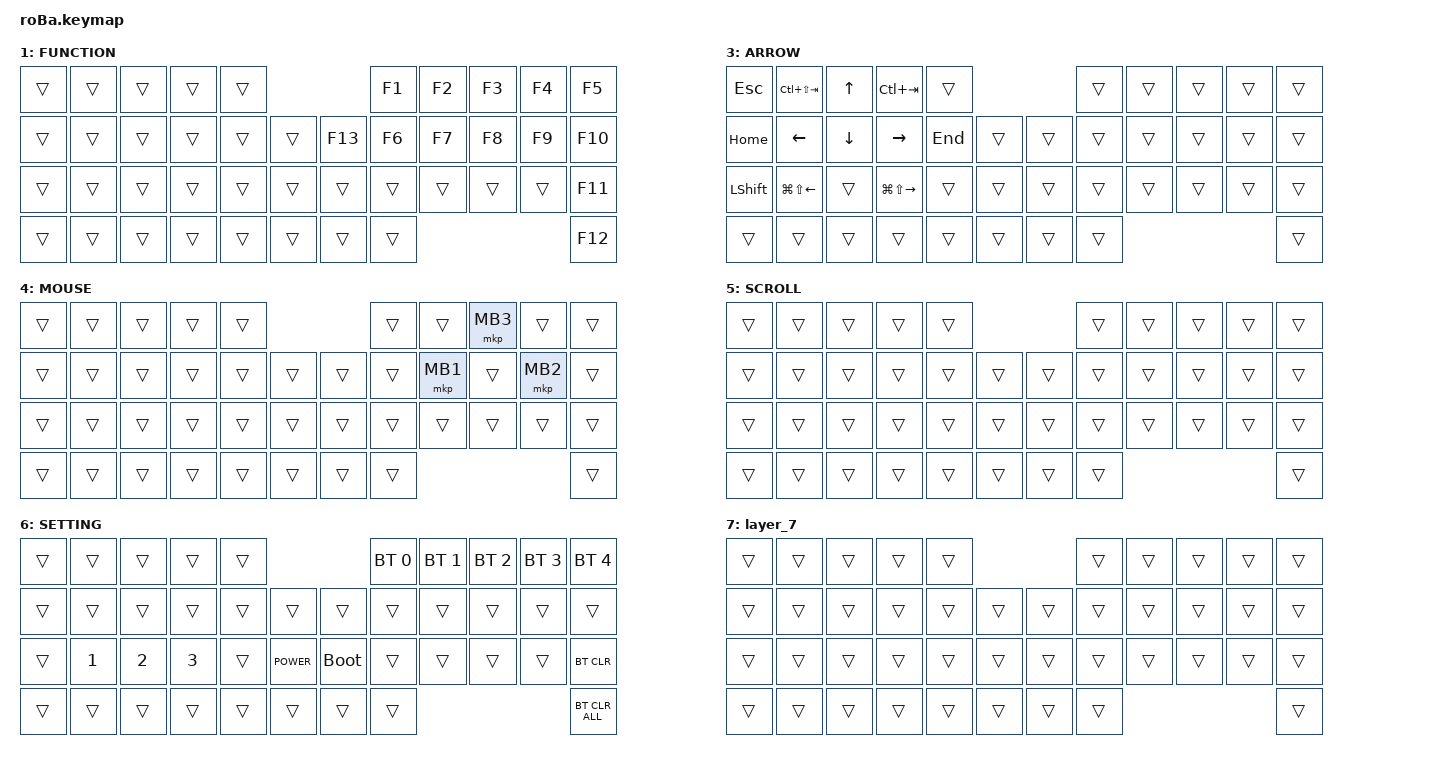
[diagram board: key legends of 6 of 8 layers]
#include <behaviors.dtsi>
#include <dt-bindings/zmk/bt.h>
#include <dt-bindings/zmk/keys.h>
#include <dt-bindings/zmk/pointing.h>

#define ZMK_POINTING_DEFAULT_SCRL_VAL 80

&mt {
    flavor = "balanced";
    quick-tap-ms = <0>;
};

&trackball {
    automouse-layer = <4>;
    scroll-layers = <5>;

    // arrows {
    //     layers = <3>;
    //     bindings =
    //         <&kp RIGHT_ARROW>,
    //         <&kp LEFT_ARROW>,
    //         <&kp UP_ARROW>,
    //         <&kp DOWN_ARROW>;
    //     tick = <10>;
    //     wait-ms = <5>;
    //     tap-ms = <5>;
    // };
};

/ {
    combos {
        compatible = "zmk,combos";

        tab {
            bindings = <&kp TAB>;
            key-positions = <11 12>;
        };

        shift_tab {
            bindings = <&kp LS(TAB)>;
            key-positions = <12 13>;
        };

        muhennkann {
            bindings = <&to_layer_0 INT_MUHENKAN>;
            key-positions = <11 10>;
        };

        double_quotation {
            bindings = <&kp DOUBLE_QUOTES>;
            key-positions = <20 21>;
        };

        eq {
            bindings = <&kp EQUALkp MINUS>;
            key-positions = <24 25>;
        };
    };

    macros {
        to_layer_0: to_layer_0 {
            compatible = "zmk,behavior-macro-one-param";
            #binding-cells = <1>;
            bindings = <&to 0 &macro_param_1to1 &kp MACRO_PLACEHOLDER>;
            label = "TO_LAYER_0";
        };
    };

    behaviors {
        lt_to_layer_0: lt_to_layer_0 {
            compatible = "zmk,behavior-hold-tap";
            label = "LAYER_TAP_TO_0";
            bindings = <&mo>, <&to_layer_0>;

            #binding-cells = <2>;
            tapping-term-ms = <200>;
        };
    };

    behaviors {
        encoder_msc_down_up: encoder_msc_down_up {
            compatible = "zmk,behavior-sensor-rotate";
            label = "ENCODER_MSC_DOWN_UP";
            #sensor-binding-cells = <0>;
            bindings = <&msc SCRL_DOWN>, <&msc SCRL_UP>;

            tap-ms = <20>;
        };
    };

    keymap {
        compatible = "zmk,keymap";

        default_layer {
            bindings = <
&kp Q             &kp W         &kp E         &kp R                        &kp T                                                          &kp Y        &kp U  &kp I      &kp O    &kp P
&kp A             &kp S         &kp D         &kp F                        &kp G        &kp LS(LG(S))                      &kp MINUSkp RPAR      &kp H        &kp J  &lt 5 K    &kp L    &kp SQTkp COLON
&mt LEFT_SHIFT Z  &kp X         &kp C         &kp V                        &kp B        &kp COLONkp ASTRK                          &kp SEMIkp PLUSCOLON  &kp N        &kp M  &kp COMMA  &kp DOT  &kp SLASH
&kp LCTRL         &kp LEFT_WIN  &kp LEFT_ALT  &lt_to_layer_0 6 INT_HENKAN  &lt 2 SPACE  &lt_to_layer_0 3 INT_MUHENKAN      &kp BACKSPACE  &lt 1 ENTER                             &kp DEL
            >;

            //sensor-bindings = <&inc_dec_kp PG_UP PAGE_DOWN>;

            sensor-bindings = <&encoder_msc_down_up>;
        };

        FUNCTION {
            bindings = <
&trans  &trans  &trans  &trans  &trans                       &kp F1  &kp F2  &kp F3  &kp F4  &kp F5
&trans  &trans  &trans  &trans  &trans  &trans      &kp F13  &kp F6  &kp F7  &kp F8  &kp F9  &kp F10
&trans  &trans  &trans  &trans  &trans  &trans      &trans   &trans  &trans  &trans  &trans  &kp F11
&trans  &trans  &trans  &trans  &trans  &trans      &trans   &trans                          &kp F12
            >;
        };

        NUM {
            bindings = <
&kp MINUSkp RPAR                   &kp KP_NUMBER_7  &kp KP_NUMBER_8  &kp KP_NUMBER_9  &kp PLUSkp SQT                                                   &kp CARETkp EQUAL         &kp AMPERSAND      &kp GRAVEkp SQT       &kp LEFT_PARENTHESIS  &kp RIGHT_PARENTHESIS
&kp SLASH                   &kp KP_NUMBER_4  &kp KP_NUMBER_5  &kp KP_NUMBER_6  &kp ASTERISK  &kp LC(LA(KP_NUMBER_0))      &kp UNDERSCORE  &kp EXCLAMATION   &kp ATkp MINUS_SIGN        &kp HASH        &kp DOLLAR            &kp PERCENT
&mt LEFT_SHIFT KP_NUMBER_0  &kp KP_NUMBER_1  &kp KP_NUMBER_2  &kp KP_NUMBER_3  &kp PERIOD    &kp EQUALkp MINUS                    &trans          &kp LEFT_BRACKET  &kp RIGHT_BRACKET  &kp LEFT_BRACE  &kp RIGHT_BRACE       &kp BACKSLASH
&trans                      &trans           &trans           &trans           &trans        &trans                       &trans          &trans                                                                     &kp PIPE
            >;
        };

        ARROW {
            bindings = <
&kp ESCAPE      &kp LC(LS(TAB))         &kp UP_ARROW    &kp LC(TAB)              &trans                       &trans  &trans  &trans  &trans  &trans
&kp HOME        &kp LEFT_ARROW          &kp DOWN_ARROW  &kp RIGHT_ARROW          &kp END  &trans      &trans  &trans  &trans  &trans  &trans  &trans
&kp LEFT_SHIFT  &kp LG(LS(LEFT_ARROW))  &trans          &kp LG(LS(RIGHT_ARROW))  &trans   &trans      &trans  &trans  &trans  &trans  &trans  &trans
&trans          &trans                  &trans          &trans                   &trans   &trans      &trans  &trans                          &trans
            >;

            sensor-bindings = <&inc_dec_kp LC(PAGE_UP) LC(PAGE_DOWN)>;
        };

        MOUSE {
            bindings = <
&trans  &trans  &trans  &trans  &trans                      &trans  &trans    &mkp MB3  &trans    &trans
&trans  &trans  &trans  &trans  &trans  &trans      &trans  &trans  &mkp MB1  &trans    &mkp MB2  &trans
&trans  &trans  &trans  &trans  &trans  &trans      &trans  &trans  &trans    &trans    &trans    &trans
&trans  &trans  &trans  &trans  &trans  &trans      &trans  &trans                                &trans
            >;
        };

        SCROLL {
            bindings = <
&trans  &trans  &trans  &trans  &trans                      &trans  &trans  &trans  &trans  &trans
&trans  &trans  &trans  &trans  &trans  &trans      &trans  &trans  &trans  &trans  &trans  &trans
&trans  &trans  &trans  &trans  &trans  &trans      &trans  &trans  &trans  &trans  &trans  &trans
&trans  &trans  &trans  &trans  &trans  &trans      &trans  &trans                          &trans
            >;
        };

        SETTING {
            bindings = <
&trans  &trans        &trans        &trans        &trans                                &bt BT_SEL 0  &bt BT_SEL 1  &bt BT_SEL 2  &bt BT_SEL 3  &bt BT_SEL 4
&trans  &trans        &trans        &trans        &trans  &trans           &trans       &trans        &trans        &trans        &trans        &trans
&trans  &kp NUMBER_1  &kp NUMBER_2  &kp NUMBER_3  &trans  &kp C_POWER      &bootloader  &trans        &trans        &trans        &trans        &bt BT_CLR
&trans  &trans        &trans        &trans        &trans  &trans           &trans       &trans                                                  &bt BT_CLR_ALL
            >;
        };

        layer_7 {
            bindings = <
&trans  &trans  &trans  &trans  &trans                      &trans  &trans  &trans  &trans  &trans
&trans  &trans  &trans  &trans  &trans  &trans      &trans  &trans  &trans  &trans  &trans  &trans
&trans  &trans  &trans  &trans  &trans  &trans      &trans  &trans  &trans  &trans  &trans  &trans
&trans  &trans  &trans  &trans  &trans  &trans      &trans  &trans                          &trans
            >;
        };
    };
};
